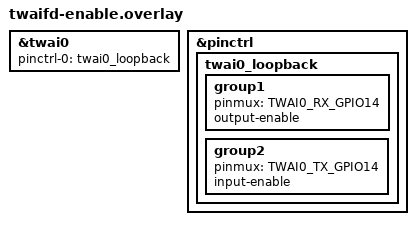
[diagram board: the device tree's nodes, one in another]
/*
 * Copyright (c) 2026 Espressif Systems (Shanghai) Co., Ltd.
 *
 * SPDX-License-Identifier: Apache-2.0
 */

&twai0 {
	status = "okay";
	pinctrl-0 = <&twai0_loopback>;
	pinctrl-names = "default";
};

&pinctrl {
	twai0_loopback: twai0_loopback {
		group1 {
			pinmux = <TWAI0_RX_GPIO14>;
			output-enable;	/* enable internal loopback */
		};

		group2 {
			pinmux = <TWAI0_TX_GPIO14>;
			input-enable;	/* enable internal loopback */
		};
	};
};
